# STM32H743 register map
File version: 2.4
CPU: CM7 r0p1, little endian, MPU, FPU, 4 interrupt priority bits
Registers are 32-bit, read-write, reset 0x0 unless marked. A register's access mark holds for its fields unless they carry their own. Offsets are from the block's base; [hi:lo] are bit positions; {n}, {i} and the like mark numbered series; 'fields as' and 'values as' point back to an identical list.

## SAI4 — 串行音频接口
Base 0x58005400
Same registers: SAI1 0x40015800, SAI2 0x40015C00, SAI3 0x40016000
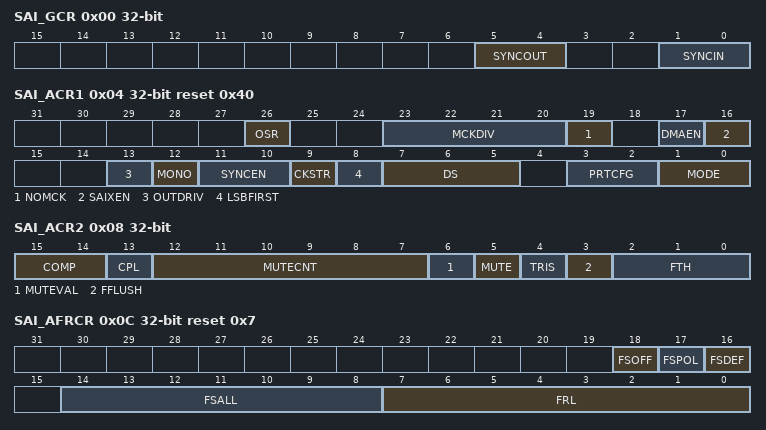
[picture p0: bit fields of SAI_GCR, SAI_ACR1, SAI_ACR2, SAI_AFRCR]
0x00 SAI_GCR — 全局配置寄存器
  [5:4] SYNCOUT — 同步输出。这些位由软件置位或清零。
  [1:0] SYNCIN — 同步输入
0x04 SAI_ACR1 reset 0x40 — 配置寄存器 1
  [26] OSR — 主时钟过采样比
  [23:20] MCKDIV — 主时钟分频器。这些位由软件置位或清零。当音频模块工作在从模式时，这些位无意义。须在音频模块禁用时进行配置。其他：主时钟频率按以下公式计算：
  [19] NOMCK — 无分频器
  [17] DMAEN — DMA 使能。该位由软件置位或清零。注意：由于复位后音频模块默认作为发送器工作，因此在置位 DMAEN 之前须先配置 MODE[1:0] 位，以避免在接收模式下产生 DMA 请求。
  [16] SAIXEN — 音频模块使能（x 为 A 或 B）。该位由软件置位。若要关闭音频模块，应用软件须将此位写为 0 并轮询该位直至回读为 0，表示模块已完全禁用。在将此位置 1 之前，请确认其为 0，否则使能命令不会被响应。该位用于控制 SAIx 音频模块的状态。若在音频帧传输进行中将其禁用，则正在进行的传输将完成，并在该音频帧传输结束后完全禁用该单元。注意：当 SAIx 模块配置为主模式时，须在 SAIXEN 位置位之前确保 SAIx 输入端已有时钟信号。
  [13] OUTDRIV — 输出驱动。该位由软件置位或清零。注意：该位须在使能音频模块之前、完成音频模块配置之后置位。
  [12] MONO — 单声道模式。该位由软件置位或清零。仅当时隙数量等于 2 时有效。当选择单声道模式时，若音频模块作为发送器工作，时隙 0 的数据将复制到时隙 1。在接收模式下，时隙 1 被丢弃，仅存储从时隙 0 接收到的数据。更多细节请参考章节：单声道/立体声模式。
  [11:10] SYNCEN — 同步使能。这些位由软件置位或清零。须在音频子模块禁用时进行配置。注意：当 SPDIF 模式使能时，音频子模块应配置为异步模式。
  [9] CKSTR — 时钟选通边沿。该位由软件置位或清零。须在音频模块禁用时进行配置。该位在 SPDIF 音频协议中无意义。
  [8] LSBFIRST — 最低有效位优先。该位由软件置位或清零。须在音频模块禁用时进行配置。该位在 AC97 音频协议中无意义，因为 AC97 数据始终以 MSB 优先传输。该位在 SPDIF 音频协议中也无意义，因为 SPDIF 数据始终以 LSB 优先传输。
  [7:5] DS — 数据位宽。这些位由软件置位或清零。当选择 SPDIF 协议时（PRTCFG[1:0] 位），由于帧长和数据位宽在此模式下是固定的，这些位将被忽略。当通过 COMP[1:0] 位选择压扩模式时，DS[1:0] 也将被忽略，因为算法已将数据位宽固定为 8 位。须在音频模块禁用时进行配置。
  [3:2] PRTCFG — 协议配置。这些位由软件置位或清零。须在音频模块禁用时进行配置。
  [1:0] MODE — SAIx 音频模块模式
0x08 SAI_ACR2 access per field — 配置寄存器 2
  [15:14] COMP rw — 压扩模式。这些位由软件置位或清零。μ-Law 和 A-Law 对数压扩是 CCITT G.711 建议的一部分，所使用的补码类型取决于 CPL 位。数据扩展或数据压缩由 MODE[0] 位的状态决定。若音频模块配置为发送器，则进行数据压缩。若音频模块配置为接收器，则自动进行数据扩展。更多细节请参考章节：压扩模式。注意：压扩模式仅在选择 TDM 时适用。
  [13] CPL rw — 补码位。该位由软件置位或清零。用于定义压扩模式中所使用的补码类型。注意：该位仅在压扩模式为 μ-Law 算法或 A-Law 算法时有效。
  [12:7] MUTECNT rw — 静音计数器。这些位由软件置位或清零。仅在接收模式下使用。这些位中设置的值用于与接收中检测到的连续静音帧数量进行比较。当静音帧数量等于此值时，标志位 MUTEDET 将置位，若 MUTEDETIE 位已使能则会产生中断。更多细节请参考章节：静音模式。
  [6] MUTEVAL rw — 静音值。该位由软件置位或清零。须在使能音频模块（SAIXEN）之前写入。仅当音频模块作为发送器工作、时隙数量小于或等于 2 且 MUTE 位置位时有效。若声明了更多时隙，在静音模式下发送的位值始终为 0，无论 MUTEVAL 的值如何。若时隙数量小于或等于 2 且 MUTEVAL = 1，则每个时隙发送的静音值为前一帧中对应时隙的值。更多细节请参考章节：静音模式。注意：该位对 SPDIF 音频模块无意义，不应使用。
  [5] MUTE rw — 静音。该位由软件置位或清零。仅当音频模块作为发送器工作时有效。若时隙数量小于或等于 2，MUTE 的值与 MUTEVAL 的值关联；若时隙数量大于 2，则等于 0。更多细节请参考章节：静音模式。注意：该位对 SPDIF 音频模块无意义，不应使用。
  [4] TRIS rw — 数据线三态管理。该位由软件置位或清零。仅当音频模块配置为发送器时有效。当音频模块配置为 SPDIF 模式时不使用该位。应在 SAI 禁用时配置。更多细节请参考章节：非活跃时隙的输出数据线管理。
  [3] FFLUSH wo — FIFO 刷新。该位由软件置位。读取时始终返回 0。该位应在 SAI 禁用时配置。
  [2:0] FTH rw — FIFO 阈值。该位由软件置位或清零。
0x0C SAI_AFRCR access per field reset 0x7 — 该寄存器在 AC97 和 SPDIF 音频协议中无意义
  [18] FSOFF rw — 帧同步偏移。该位由软件置位或清零。该位在 AC97 或 SPDIF 音频模块配置中无意义且不被使用。须在音频模块禁用时进行配置。
  [17] FSPOL rw — 帧同步极性。该位由软件置位或清零。用于配置 FS 信号上帧起始的电平。该位在 AC97 或 SPDIF 音频模块配置中无意义且不被使用。须在音频模块禁用时进行配置。
  [16] FSDEF ro — 帧同步定义。该位由软件置位或清零。当该位置位时，SAI_xSLOTR 寄存器中定义的时隙数量必须为偶数。这意味着其中一半时隙将分配给左声道，另一半分配给右声道（例如：对于 I2S 或 MSB/LSB 对齐协议，此位须置位）。该位在 AC97 或 SPDIF 音频模块配置中无意义且不被使用。须在音频模块禁用时进行配置。
  [14:8] FSALL rw — 帧同步有效电平长度。这些位由软件置位或清零。用于指定 FS 信号在音频帧中有效电平的位时钟（SCK）周期数 + 1（FSALL[6:0] + 1）。这些位在 AC97 或 SPDIF 音频模块配置中无意义且不被使用。须在音频模块禁用时进行配置。
  [7:0] FRL rw — 帧长。这些位由软件置位或清零。用于定义以 SCK 时钟周期数表示的音频帧长度：帧中的位数等于 FRL[7:0] + 1。音频帧中传输的最小位数必须为 8，否则音频模块将出现异常行为。例如，当数据位宽为 8 位且在 SAI_xSLOTR 寄存器中仅定义了一个时隙 0（NBSLOT[3:0] = 0000）时，就属于最小位数不足的情况。在主模式下，若使用了主时钟（可通过 MCLK_x 引脚获取），帧长应对齐到一个 2 的幂次数，范围为 8 到 256。当不使用主时钟时（NODIV = 1），建议将帧长配置为 8 到 256 之间的值。这些位在 AC97 或 SPDIF 音频模块配置中无意义且不被使用。
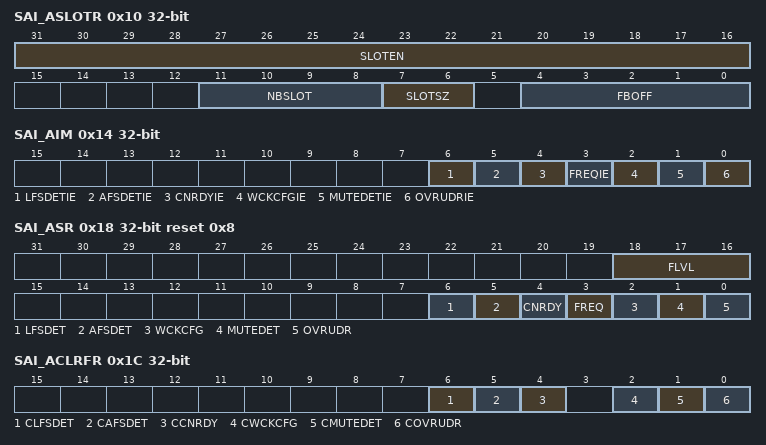
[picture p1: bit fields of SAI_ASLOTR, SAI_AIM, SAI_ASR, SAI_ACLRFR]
0x10 SAI_ASLOTR — 该寄存器在 AC97 和 SPDIF 音频协议中无意义
  [31:16] SLOTEN — 时隙使能。这些位由软件置位或清零。每个 SLOTEN 位对应一个时隙位置，从 0 到 15（最多 16 个时隙）。须在音频模块禁用时使能时隙。在 AC97 或 SPDIF 模式下将被忽略。
  [11:8] NBSLOT — 音频帧中的时隙数。这些位由软件置位或清零。该位域的值表示音频帧中的时隙数 + 1（包括非活跃时隙）。最大时隙数为 16。若 SAI_xFRCR 寄存器中的 FSDEF 位置位，时隙数应为偶数。须在音频模块禁用时配置时隙数。在 AC97 或 SPDIF 模式下将被忽略。
  [7:6] SLOTSZ — 时隙大小。这些位由软件置位或清零。时隙大小必须大于或等于数据位宽。若不满足此条件，SAI 的行为将是不确定的。有关如何驱动 SD 线的信息，请参考章节：非活跃时隙的输出数据线管理。须在音频模块禁用时设置这些位。在 AC97 或 SPDIF 模式下将被忽略。
  [4:0] FBOFF — 首比特偏移。这些位由软件置位或清零。该位域的值定义了时隙中第一个数据传输位的位置，表示一个偏移量。在发送模式下，数据字段之外的位被强制置为 0。在接收模式下，多余的接收位将被丢弃。须在音频模块禁用时设置这些位。在 AC97 或 SPDIF 模式下将被忽略。
0x14 SAI_AIM — 中断屏蔽寄存器 2
  [6] LFSDETIE — 帧同步滞后检测中断使能。该位由软件置位或清零。当该位置位时，若 SAI_xSR 寄存器中的 LFSDET 位置位，则产生中断。该位在 AC97、SPDIF 模式或音频模块作为主模式工作时无意义。
  [5] AFSDETIE — 帧同步提前检测中断使能。该位由软件置位或清零。当该位置位时，若 SAI_xSR 寄存器中的 AFSDET 位置位，则产生中断。该位在 AC97、SPDIF 模式或音频模块作为主模式工作时无意义。
  [4] CNRDYIE — 编解码器未就绪中断使能（AC97）。该位由软件置位或清零。当中断使能时，音频模块在 AC97 帧的时隙 0（tag0）中检测连接到该线路的编解码器是否就绪。若未就绪，SAI_xSR 寄存器中的 CNRDY 标志位将置位并产生中断。该位仅当通过 PRTCFG[1:0] 位选择 AC97 模式且音频模块作为接收器工作时有效。
  [3] FREQIE — FIFO 请求中断使能。该位由软件置位或清零。当该位置位时，若 SAI_xSR 寄存器中的 FREQ 位置位，则产生中断。由于复位后音频模块默认作为发送器工作，因此在置位 FREQIE 之前须先配置 MODE 位，以避免在接收模式下产生误中断。
  [2] WCKCFGIE — 时钟配置错误中断使能。该位由软件置位或清零。仅在音频模块配置为主模式（MODE[1] = 0）且 NODIV = 0 时才被响应。若 SAI_xSR 寄存器中的 WCKCFG 标志位置位，则产生中断。注意：该位仅在 TDM 模式下使用，在其他模式下无意义。
  [1] MUTEDETIE — 静音检测中断使能。该位由软件置位或清零。当该位置位时，若 SAI_xSR 寄存器中的 MUTEDET 位置位，则产生中断。该位仅在音频模块配置为接收模式时有效。
  [0] OVRUDRIE — 溢出/欠载中断使能。该位由软件置位或清零。当该位置位时，若 SAI_xSR 寄存器中的 OVRUDR 位置位，则产生中断。
0x18 SAI_ASR ro reset 0x8 — 状态寄存器
  [18:16] FLVL — FIFO 电平阈值。该位为只读。FIFO 电平阈值标志位仅由硬件管理，其设置取决于 SAI 模块的配置（发送或接收模式）。若 SAI 模块配置为发送器：若 SAI 模块配置为接收器：
  [6] LFSDET — 帧同步滞后检测。该位为只读。仅在音频模块配置为从模式时该标志位才可置位。在 AC97 或 SPDIF 模式下不使用。若 SAI_xIM 寄存器中的 LFSDETIE 位置位，可产生中断。当软件将 SAI_xCLRFR 寄存器中的 CLFSDET 位置位时，该标志位被清除。
  [5] AFSDET — 帧同步提前检测。该位为只读。仅在音频模块配置为从模式时该标志位才可置位。在 AC97 或 SPDIF 模式下不使用。若 SAI_xIM 寄存器中的 AFSDETIE 位置位，可产生中断。当软件将 SAI_xCLRFR 寄存器中的 CAFSDET 位置位时，该标志位被清除。
  [4] CNRDY — 编解码器未就绪。该位为只读。仅在 SAI_xCR1 寄存器中选择了 AC97 音频协议且配置为接收模式时使用。若 SAI_xIM 寄存器中的 CNRDYIE 位置位，可产生中断。当软件将 SAI_xCLRFR 寄存器中的 CCNRDY 位置位时，该标志位被清除。
  [3] FREQ — FIFO 请求。该位为只读。请求取决于音频模块的配置：若模块配置为发送模式，FIFO 请求关联到对 SAI_xDR 的写请求操作。若模块配置为接收模式，FIFO 请求关联到从 SAI_xDR 的读请求操作。若 SAI_xIM 寄存器中的 FREQIE 位置位，该标志位可产生中断。
  [2] WCKCFG — 时钟配置错误标志位。该位为只读。仅在音频模块工作于主模式（MODE[1] = 0）且 NODIV = 0 时使用。若 SAI_xIM 寄存器中的 WCKCFGIE 位置位，可产生中断。当软件将 SAI_xCLRFR 寄存器中的 CWCKCFG 位置位时，该标志位被清除。
  [1] MUTEDET — 静音检测。该位为只读。若在给定音频帧的每个时隙中连续接收到 0 值，且持续了连续的音频帧数（由 SAI_xCR2 寄存器中的 MUTECNT 位设置），则该标志位置位。若 SAI_xIM 寄存器中的 MUTEDETIE 位置位，可产生中断。当软件将 SAI_xCLRFR 寄存器中的 CMUTEDET 位置位时，该标志位被清除。
  [0] OVRUDR — 溢出/欠载。该位为只读。溢出和欠载状态分别仅在音频模块配置为接收器和发送器时才会发生。若 SAI_xIM 寄存器中的 OVRUDRIE 位置位，可产生中断。当软件将 SAI_xCLRFR 寄存器中的 COVRUDR 位置位时，该标志位被清除。
0x1C SAI_ACLRFR wo — 清除标志寄存器
  [6] CLFSDET — 清除帧同步滞后检测标志。该位为只写。将此位写 1 可清除 SAI_xSR 寄存器中的 LFSDET 标志位。在 AC97 或 SPDIF 模式下不使用。读取该位始终返回 0。
  [5] CAFSDET — 清除帧同步提前检测标志。该位为只写。将此位写 1 可清除 SAI_xSR 寄存器中的 AFSDET 标志位。在 AC97 或 SPDIF 模式下不使用。读取该位始终返回 0。
  [4] CCNRDY — 清除编解码器未就绪标志。该位为只写。将此位写 1 可清除 SAI_xSR 寄存器中的 CNRDY 标志位。仅在 SAI_xCR1 寄存器中选择了 AC97 音频协议时使用。读取该位始终返回 0。
  [2] CWCKCFG — 清除时钟配置错误标志。该位为只写。将此位写 1 可清除 SAI_xSR 寄存器中的 WCKCFG 标志位。仅在音频模块设置为主模式（MODE[1] = 0）且 SAI_xCR1 寄存器中 NODIV = 0 时使用。读取该位始终返回 0。
  [1] CMUTEDET — 清除静音检测标志。该位为只写。将此位写 1 可清除 SAI_xSR 寄存器中的 MUTEDET 标志位。读取该位始终返回 0。
  [0] COVRUDR — 清除溢出/欠载标志。该位为只写。将此位写 1 可清除 SAI_xSR 寄存器中的 OVRUDR 标志位。读取该位始终返回 0。
0x20 SAI_ADR — 数据寄存器
  [31:0] DATA — 数据。向该寄存器写入数据时，若 FIFO 未满，则将数据加载到 FIFO 中。从该寄存器读取数据时，若 FIFO 非空，则清空 FIFO 中的一项。
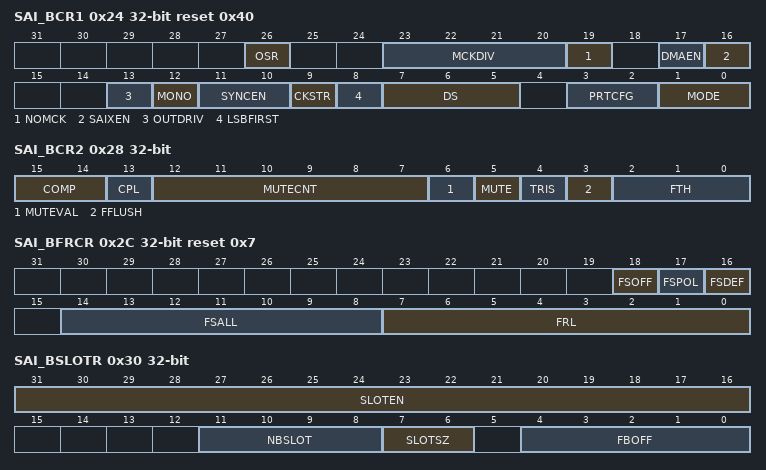
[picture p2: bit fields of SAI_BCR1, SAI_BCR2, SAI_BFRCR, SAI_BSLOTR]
0x24 SAI_BCR1 reset 0x40 — 配置寄存器 1
  fields as SAI_ACR1
0x28 SAI_BCR2 access per field — 配置寄存器 2
  fields as SAI_ACR2
0x2C SAI_BFRCR access per field reset 0x7 — 该寄存器在 AC97 和 SPDIF 音频协议中无意义
  fields as SAI_AFRCR
0x30 SAI_BSLOTR — 该寄存器在 AC97 和 SPDIF 音频协议中无意义
  fields as SAI_ASLOTR
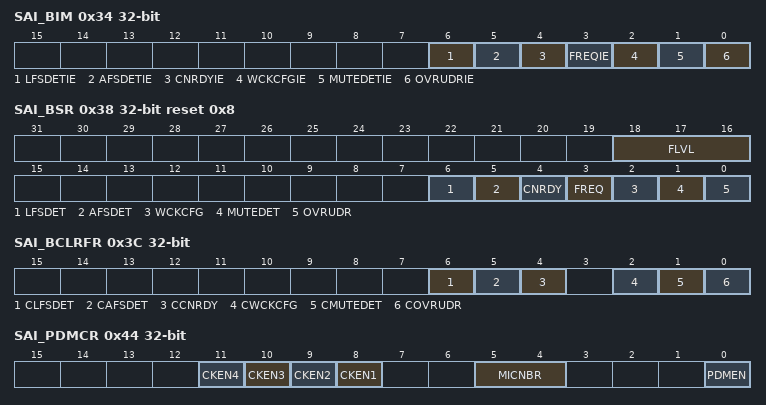
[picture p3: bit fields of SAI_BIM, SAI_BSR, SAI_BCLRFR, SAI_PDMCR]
0x34 SAI_BIM — 中断屏蔽寄存器 2
  fields as SAI_AIM
0x38 SAI_BSR ro reset 0x8 — 状态寄存器
  fields as SAI_ASR
0x3C SAI_BCLRFR wo — 清除标志寄存器
  fields as SAI_ACLRFR
0x40 SAI_BDR — 数据寄存器
  fields as SAI_ADR
0x44 SAI_PDMCR — PDM 控制寄存器
  [n+7] CKEN{n} (n=1..4) — 位流时钟 {n} 的时钟使能
  [5:4] MICNBR — 麦克风数量
  [0] PDMEN — PDM 使能
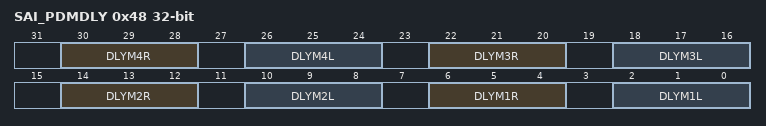
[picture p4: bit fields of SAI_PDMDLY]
0x48 SAI_PDMDLY — PDM 延迟寄存器
  [30:28] DLYM4R — 第 4 对麦克风中第二个麦克风的延迟线
  [26:24] DLYM4L — 第 4 对麦克风中第一个麦克风的延迟线
  [22:20] DLYM3R — 第 3 对麦克风中第二个麦克风的延迟线
  [18:16] DLYM3L — 第 3 对麦克风中第一个麦克风的延迟线
  [14:12] DLYM2R — 第 2 对麦克风中第二个麦克风的延迟线
  [10:8] DLYM2L — 第 2 对麦克风中第一个麦克风的延迟线
  [6:4] DLYM1R — 第 1 对麦克风中第二个麦克风的延迟线调整
  [2:0] DLYM1L — 第 1 对麦克风中第一个麦克风的延迟线调整
